VERSION "1.0"

BU_: ECU Dashboard Logger

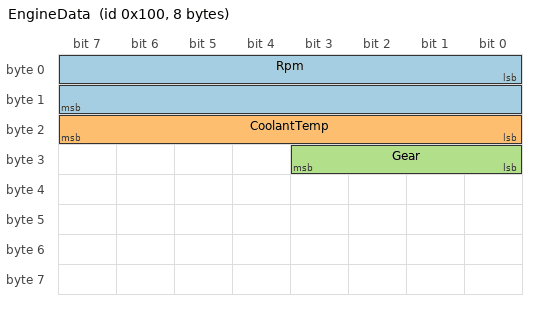
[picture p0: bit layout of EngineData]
BO_ 256 EngineData: 8 ECU
 SG_ Rpm : 0|16@1+ (0.25,0) [0|16383.75] "rpm" Dashboard,Logger
 SG_ CoolantTemp : 16|8@1- (1,-40) [-40|215] "degC" Dashboard
 SG_ Gear : 24|4@1+ (1,0) [0|7] "" Dashboard

BO_ 512 BodyControl: 2 Dashboard
 SG_ Mux M : 0|8@1+ (1,0) [0|255] "" ECU
 SG_ DoorState m0 : 8|4@1+ (1,0) [0|15] "" ECU

BO_ 768 Transmission: 1 ECU
 SG_ Direction : 0|4@1- (1,0) [-8|7] "" Dashboard

VAL_ 256 Gear 0 "Neutral" 1 "First" 2 "Second" ;
VAL_ 768 Direction -1 "Reverse" 0 "Neutral" 1 "Forward" ;
